# earlgrey register map
Vendor: lowRISC; File version: 0.1
CPU: ibex rev01, little endian, no MPU, no FPU, VTOR, 2 interrupt priority bits, 2 interrupts
Registers are 32-bit, read-write, no defined reset value unless marked. A register's access mark holds for its fields unless they carry their own. Offsets are from the block's base; [hi:lo] are bit positions.

## UART0 — Full duplex serial communication interface, supports bit rates of up to 1 Mbit/s
Base 0x40000000
Same registers: UART1 0x40010000, UART2 0x40020000, UART3 0x40030000
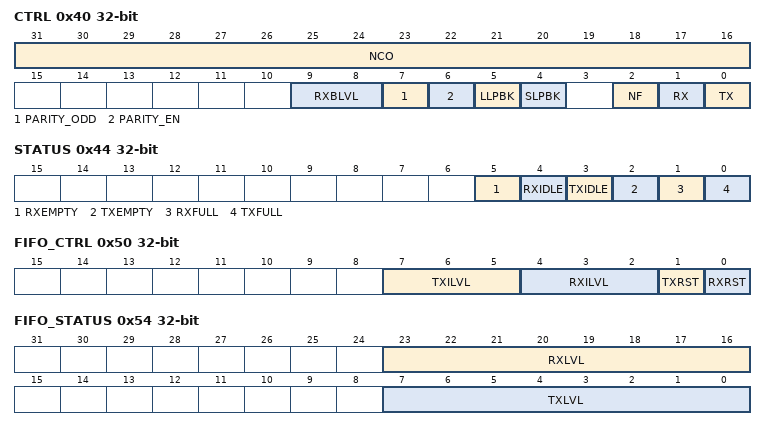
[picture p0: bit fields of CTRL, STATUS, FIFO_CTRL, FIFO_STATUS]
0x40 CTRL — UART control register
  [31:16] NCO — BAUD clock rate control.
  [9:8] RXBLVL — Trigger level for RX break detection. Sets the number of charactertimes the line must be low to detect a break.
  [7] PARITY_ODD — If PARITY_EN is true, this determines the type, 1 for odd parity, 0 for even.
  [6] PARITY_EN — If true, parity is enabled in both RX and TX directions.
  [5] LLPBK — Line loopback enable.If this bit is turned on, incoming bits are forwarded to TX for testing purpose.See Block Diagram. Note that the internal design sees RX value as 1 always if lineloopback is enabled.
  [4] SLPBK — System loopback enable.If this bit is turned on, any outgoing bits to TX are received through RX.See Block Diagram. Note that the TX line goes 1 if System loopback is enabled.
  [2] NF — RX noise filter enable.If the noise filter is enabled, RX line goes through the 3-taprepetition code. It ignores single IP clock period noise.
  [1] RX — RX enable
  [0] TX — TX enable
0x44 STATUS ro — UART live status register
  [5] RXEMPTY — RX FIFO is empty
  [4] RXIDLE — RX is idle
  [3] TXIDLE — TX FIFO is empty and all bits have been transmitted
  [2] TXEMPTY — TX FIFO is empty
  [1] RXFULL — RX buffer is full
  [0] TXFULL — TX buffer is full
0x48 RDATA ro — UART read data
  [7:0] Value
0x4C WDATA wo — UART write data
  [7:0] Value
0x50 FIFO_CTRL — UART FIFO control register
  [7:5] TXILVL — Trigger level for TX interrupts. If the FIFO depth is less than the setting, itraises tx_watermark interrupt.
  [4:2] RXILVL — Trigger level for RX interrupts. If the FIFO depth is greater than or equal tothe setting, it raises rx_watermark interrupt.
  [1] TXRST — TX fifo reset. Write 1 to the register resets TX_FIFO. Read returns 0
  [0] RXRST — RX fifo reset. Write 1 to the register resets RX_FIFO. Read returns 0
0x54 FIFO_STATUS ro — UART FIFO status register
  [23:16] RXLVL — Current fill level of RX fifo
  [7:0] TXLVL — Current fill level of TX fifo
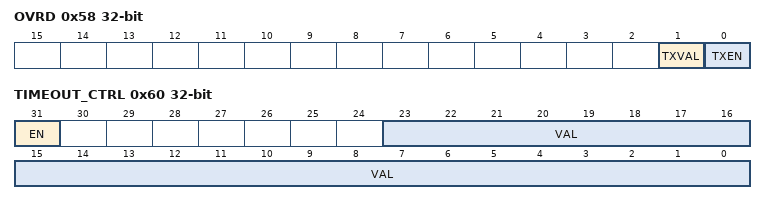
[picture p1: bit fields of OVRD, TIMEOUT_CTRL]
0x58 OVRD — TX pin override control. Gives direct SW control over TX pin state
  [1] TXVAL — Write to set the value of the TX pin
  [0] TXEN — Enable TX pin override control
0x5C VAL ro — UART oversampled values
  [15:0] RX — Last 16 oversampled values of RX. Most recent bit is bit 0, oldest 15.
0x60 TIMEOUT_CTRL — UART RX timeout control
  [31] EN — Enable RX timeout feature
  [23:0] VAL — RX timeout value in UART bit times

## PATTGEN — Transmission of short time-dependent data patterns on two clock-parallel output channels
Base 0x400E0000
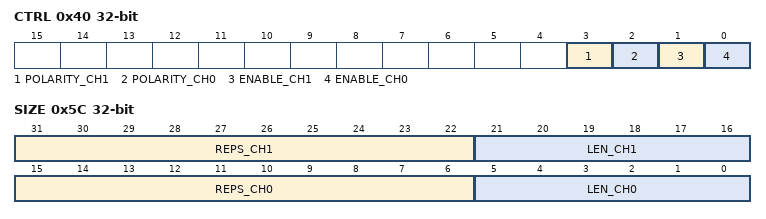
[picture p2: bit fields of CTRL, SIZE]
0x40 CTRL — PATTGEN control register
  [3] POLARITY_CH1 — Clock (`pcl`) polarity for Channel 1. If low, `pda` signal changes on falling edge of `pcl` signal, otherwise pda changes on rising edge. Note that writes to a channel's configuration registers have no effect while the channel is enabled.
  [2] POLARITY_CH0 — Clock (`pcl`) polarity for Channel 0. If low, `pda` signal changes on falling edge of pcl signal, otherwise pda changes on rising edge. Note that writes to a channel's configuration registers have no effect while the channel is enabled.
  [1] ENABLE_CH1 — Enable pattern generator functionality for Channel 1
  [0] ENABLE_CH0 — Enable pattern generator functionality for Channel 0
0x44 PREDIV_CH0 — PATTGEN pre-divider register for Channel 0
  [31:0] CLK_RATIO — Clock divider ratio fpr Channel 0 (relative to I/O clock). Note that writes to a channel's configuration registers have no effect while the channel is enabled.
0x48 PREDIV_CH1 — PATTGEN pre-divider register for Channel 1
  [31:0] CLK_RATIO — Clock divider ratio for Channel 1 (relative to I/O clock). Note that writes to a channel's configuration registers have no effect while the channel is enabled.
0x4C DATA_CH0_0 — PATTGEN seed pattern multi-registers for Channel 0.
  [31:0] DATA_0 — Seed pattern for Channel 0 (1-64 bits). Note that writes to a channel's configuration registers have no effect while the channel is enabled.
0x50 DATA_CH0_1 — PATTGEN seed pattern multi-registers for Channel 0.
  [31:0] DATA_1 — Seed pattern for Channel 0 (1-64 bits). Note that writes to a channel's configuration registers have no effect while the channel is enabled.
0x54 DATA_CH1_0 — PATTGEN seed pattern multi-registers for Channel 1.
  [31:0] DATA_0 — Seed pattern for Channel 1 (1-64 bits). Note that writes to a channel's configuration registers have no effect while the channel is enabled.
0x58 DATA_CH1_1 — PATTGEN seed pattern multi-registers for Channel 1.
  [31:0] DATA_1 — Seed pattern for Channel 1 (1-64 bits). Note that writes to a channel's configuration registers have no effect while the channel is enabled.
0x5C SIZE — PATTGEN pattern length
  [31:22] REPS_CH1 — Number of pattern repetitions for Channel 1, minus 1. Valid values: 0..1023. Note that writes to a channel's configuration registers have no effect while the channel is enabled.
  [21:16] LEN_CH1 — Length of the seed pattern for Channel 1, minus 1. Valid values: 0..63. Note that writes to a channel's configuration registers have no effect while the channel is enabled.
  [15:6] REPS_CH0 — Number of pattern repetitions for Channel 0, minus 1. Valid values: 0..1023. Note that writes to a channel's configuration registers have no effect while the channel is enabled.
  [5:0] LEN_CH0 — Length of the seed pattern for Channel 0, minus 1. Valid values: 0..63. Note that writes to a channel's configuration registers have no effect while the channel is enabled.
